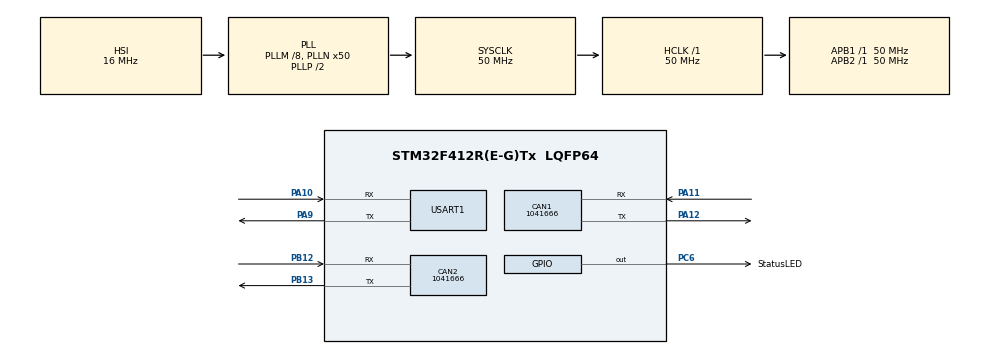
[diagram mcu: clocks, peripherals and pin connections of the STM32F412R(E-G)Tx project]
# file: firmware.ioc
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CAN1.CalculateBaudRate=1041666
CAN1.CalculateTimeBit=960
CAN1.CalculateTimeQuantum=320.0
CAN2.CalculateBaudRate=1041666
CAN2.CalculateTimeBit=960
CAN2.CalculateTimeQuantum=320.0
Mcu.Family=STM32F4
Mcu.Name=STM32F412R(E-G)Tx
Mcu.Package=LQFP64
NVIC.PriorityGroup=NVIC_PRIORITYGROUP_4
PA10.Mode=Asynchronous
PA10.Signal=USART1_RX
PA11.Mode=CAN_Activate
PA11.Signal=CAN1_RX
PA12.Mode=CAN_Activate
PA12.Signal=CAN1_TX
PA13.Mode=Trace_Asynchronous_SW
PA13.Signal=SYS_JTMS-SWDIO
PA14.Mode=Trace_Asynchronous_SW
PA14.Signal=SYS_JTCK-SWCLK
PA9.Mode=Asynchronous
PA9.Signal=USART1_TX
PB12.Mode=CAN_Activate
PB12.Signal=CAN2_RX
PB13.Mode=CAN_Activate
PB13.Signal=CAN2_TX
PB3.Mode=Trace_Asynchronous_SW
PB3.Signal=SYS_JTDO-SWO
PC6.GPIO_Label=StatusLED
PC6.Signal=GPIO_Output
PH0\ -\ OSC_IN.Mode=HSE-External-Oscillator
PH0\ -\ OSC_IN.Signal=RCC_OSC_IN
PH1\ -\ OSC_OUT.Mode=HSE-External-Oscillator
PH1\ -\ OSC_OUT.Signal=RCC_OSC_OUT
ProjectManager.HeapSize=0x200
ProjectManager.StackSize=0x400
ProjectManager.TargetToolchain=Makefile
RCC.AHBFreq_Value=50000000
RCC.APB1Freq_Value=50000000
RCC.APB1TimFreq_Value=50000000
RCC.APB2Freq_Value=50000000
RCC.APB2TimFreq_Value=50000000
RCC.CortexFreq_Value=50000000
RCC.HCLKFreq_Value=50000000
RCC.HSE_VALUE=8000000
RCC.PLLM=8
RCC.PLLN=50
RCC.SYSCLKFreq_VALUE=50000000
RCC.SYSCLKSource=RCC_SYSCLKSOURCE_PLLCLK
RCC.USBFreq_Value=50000000
RCC.VCOOutputFreq_Value=100000000
USART1.VirtualMode=VM_ASYNC
board=custom

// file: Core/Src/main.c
/* USER CODE BEGIN Header */
/**
  ******************************************************************************
  * @file           : main.c
  * @brief          : Main program body
  ******************************************************************************
  * @attention
  *
  * Copyright (c) 2024 STMicroelectronics.
  * All rights reserved.
  *
  * This software is licensed under terms that can be found in the LICENSE file
  * in the root directory of this software component.
  * If no LICENSE file comes with this software, it is provided AS-IS.
  *
  ******************************************************************************
  */
/* USER CODE END Header */
#include "main.h"

CAN_HandleTypeDef hcan1;
CAN_HandleTypeDef hcan2;

UART_HandleTypeDef huart1;

void SystemClock_Config(void);
static void MX_GPIO_Init(void);
static void MX_CAN1_Init(void);
static void MX_CAN2_Init(void);
static void MX_USART1_UART_Init(void);

int main(void)
{

  /* MCU Configuration--------------------------------------------------------*/

  /* Reset of all peripherals, Initializes the Flash interface and the Systick. */
  HAL_Init();

  /* Configure the system clock */
  SystemClock_Config();

  /* Initialize all configured peripherals */
  MX_GPIO_Init();
  MX_CAN1_Init();
  MX_CAN2_Init();
  MX_USART1_UART_Init();

  /* Infinite loop */
  /* USER CODE BEGIN WHILE */
  while (1)
  {
    HAL_GPIO_WritePin(StatusLED_GPIO_Port, StatusLED_Pin, 1);
    HAL_Delay(500);
    HAL_GPIO_WritePin(StatusLED_GPIO_Port, StatusLED_Pin, 0);
    HAL_Delay(500);
    /* USER CODE END WHILE */

  }
}

void SystemClock_Config(void)
{
  RCC_OscInitTypeDef RCC_OscInitStruct = {0};
  RCC_ClkInitTypeDef RCC_ClkInitStruct = {0};

  /** Configure the main internal regulator output voltage
  */
  __HAL_RCC_PWR_CLK_ENABLE();
  __HAL_PWR_VOLTAGESCALING_CONFIG(PWR_REGULATOR_VOLTAGE_SCALE1);

  /** Initializes the RCC Oscillators according to the specified parameters
  * in the RCC_OscInitTypeDef structure.
  */
  RCC_OscInitStruct.OscillatorType = RCC_OSCILLATORTYPE_HSI;
  RCC_OscInitStruct.HSIState = RCC_HSI_ON;
  RCC_OscInitStruct.HSICalibrationValue = RCC_HSICALIBRATION_DEFAULT;
  RCC_OscInitStruct.PLL.PLLState = RCC_PLL_ON;
  RCC_OscInitStruct.PLL.PLLSource = RCC_PLLSOURCE_HSI;
  RCC_OscInitStruct.PLL.PLLM = 8;
  RCC_OscInitStruct.PLL.PLLN = 50;
  RCC_OscInitStruct.PLL.PLLP = RCC_PLLP_DIV2;
  RCC_OscInitStruct.PLL.PLLQ = 2;
  RCC_OscInitStruct.PLL.PLLR = 2;
  if (HAL_RCC_OscConfig(&RCC_OscInitStruct) != HAL_OK)
  {
    Error_Handler();
  }

  /** Initializes the CPU, AHB and APB buses clocks
  */
  RCC_ClkInitStruct.ClockType = RCC_CLOCKTYPE_HCLK|RCC_CLOCKTYPE_SYSCLK
                              |RCC_CLOCKTYPE_PCLK1|RCC_CLOCKTYPE_PCLK2;
  RCC_ClkInitStruct.SYSCLKSource = RCC_SYSCLKSOURCE_PLLCLK;
  RCC_ClkInitStruct.AHBCLKDivider = RCC_SYSCLK_DIV1;
  RCC_ClkInitStruct.APB1CLKDivider = RCC_HCLK_DIV1;
  RCC_ClkInitStruct.APB2CLKDivider = RCC_HCLK_DIV1;

  if (HAL_RCC_ClockConfig(&RCC_ClkInitStruct, FLASH_LATENCY_1) != HAL_OK)
  {
    Error_Handler();
  }
}

static void MX_CAN1_Init(void)
{

  hcan1.Instance = CAN1;
  hcan1.Init.Prescaler = 16;
  hcan1.Init.Mode = CAN_MODE_NORMAL;
  hcan1.Init.SyncJumpWidth = CAN_SJW_1TQ;
  hcan1.Init.TimeSeg1 = CAN_BS1_1TQ;
  hcan1.Init.TimeSeg2 = CAN_BS2_1TQ;
  hcan1.Init.TimeTriggeredMode = DISABLE;
  hcan1.Init.AutoBusOff = DISABLE;
  hcan1.Init.AutoWakeUp = DISABLE;
  hcan1.Init.AutoRetransmission = DISABLE;
  hcan1.Init.ReceiveFifoLocked = DISABLE;
  hcan1.Init.TransmitFifoPriority = DISABLE;
  if (HAL_CAN_Init(&hcan1) != HAL_OK)
  {
    Error_Handler();
  }

}

static void MX_CAN2_Init(void)
{

  hcan2.Instance = CAN2;
  hcan2.Init.Prescaler = 16;
  hcan2.Init.Mode = CAN_MODE_NORMAL;
  hcan2.Init.SyncJumpWidth = CAN_SJW_1TQ;
  hcan2.Init.TimeSeg1 = CAN_BS1_1TQ;
  hcan2.Init.TimeSeg2 = CAN_BS2_1TQ;
  hcan2.Init.TimeTriggeredMode = DISABLE;
  hcan2.Init.AutoBusOff = DISABLE;
  hcan2.Init.AutoWakeUp = DISABLE;
  hcan2.Init.AutoRetransmission = DISABLE;
  hcan2.Init.ReceiveFifoLocked = DISABLE;
  hcan2.Init.TransmitFifoPriority = DISABLE;
  if (HAL_CAN_Init(&hcan2) != HAL_OK)
  {
    Error_Handler();
  }

}

static void MX_USART1_UART_Init(void)
{

  huart1.Instance = USART1;
  huart1.Init.BaudRate = 115200;
  huart1.Init.WordLength = UART_WORDLENGTH_8B;
  huart1.Init.StopBits = UART_STOPBITS_1;
  huart1.Init.Parity = UART_PARITY_NONE;
  huart1.Init.Mode = UART_MODE_TX_RX;
  huart1.Init.HwFlowCtl = UART_HWCONTROL_NONE;
  huart1.Init.OverSampling = UART_OVERSAMPLING_16;
  if (HAL_UART_Init(&huart1) != HAL_OK)
  {
    Error_Handler();
  }

}

static void MX_GPIO_Init(void)
{
  GPIO_InitTypeDef GPIO_InitStruct = {0};

  /* GPIO Ports Clock Enable */
  __HAL_RCC_GPIOH_CLK_ENABLE();
  __HAL_RCC_GPIOB_CLK_ENABLE();
  __HAL_RCC_GPIOC_CLK_ENABLE();
  __HAL_RCC_GPIOA_CLK_ENABLE();

  /*Configure GPIO pin Output Level */
  HAL_GPIO_WritePin(StatusLED_GPIO_Port, StatusLED_Pin, GPIO_PIN_RESET);

  /*Configure GPIO pin : StatusLED_Pin */
  GPIO_InitStruct.Pin = StatusLED_Pin;
  GPIO_InitStruct.Mode = GPIO_MODE_OUTPUT_PP;
  GPIO_InitStruct.Pull = GPIO_NOPULL;
  GPIO_InitStruct.Speed = GPIO_SPEED_FREQ_LOW;
  HAL_GPIO_Init(StatusLED_GPIO_Port, &GPIO_InitStruct);

}

void Error_Handler(void)
{
  __disable_irq();
  while (1)
  {
  }
}
